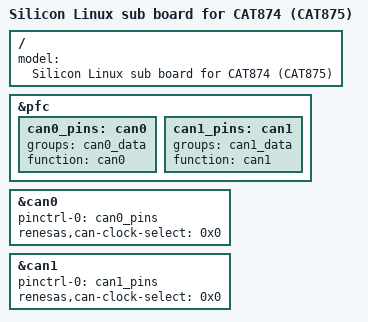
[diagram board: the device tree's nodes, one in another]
// SPDX-License-Identifier: GPL-2.0
/*
 * Device Tree Source for the Silicon Linux sub board for CAT874 (CAT875)
 *
 * Copyright (C) 2019 Renesas Electronics Corp.
 */

/ {
	model = "Silicon Linux sub board for CAT874 (CAT875)";
};

&pfc {
	can0_pins: can0 {
		groups = "can0_data";
		function = "can0";
	};

	can1_pins: can1 {
		groups = "can1_data";
		function = "can1";
	};
};

&can0 {
	pinctrl-0 = <&can0_pins>;
	pinctrl-names = "default";
	renesas,can-clock-select = <0x0>;
	status = "okay";
};

&can1 {
	pinctrl-0 = <&can1_pins>;
	pinctrl-names = "default";
	renesas,can-clock-select = <0x0>;
	status = "okay";
};
